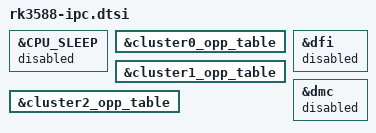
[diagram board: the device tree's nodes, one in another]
// SPDX-License-Identifier: (GPL-2.0+ OR MIT)
/*
 * Copyright (c) 2022 Rockchip Electronics Co., Ltd.
 *
 */

#include "rk3588-linux.dtsi"

&CPU_SLEEP {
	status = "disabled";
};

&cluster0_opp_table {
	/delete-node/ opp-408000000;
	/delete-node/ opp-600000000;
	/delete-node/ opp-816000000;
	/delete-node/ opp-1008000000;
};

&cluster1_opp_table {
	/delete-node/ opp-408000000;
	/delete-node/ opp-600000000;
	/delete-node/ opp-816000000;
	/delete-node/ opp-1008000000;
	/delete-node/ opp-2256000000;
	/delete-node/ opp-2304000000;
	/delete-node/ opp-2352000000;
	/delete-node/ opp-2400000000;
};

&cluster2_opp_table {
	/delete-node/ opp-408000000;
	/delete-node/ opp-600000000;
	/delete-node/ opp-816000000;
	/delete-node/ opp-1008000000;
	/delete-node/ opp-2256000000;
	/delete-node/ opp-2304000000;
	/delete-node/ opp-2352000000;
	/delete-node/ opp-2400000000;
};

&dfi {
	status = "disabled";
};

&dmc {
	status = "disabled";
};
